# CY8C5888AXI_LP096 register map
File version: 0.1
CY8C58LP
Registers are 8-bit, read-write, no defined reset value unless marked. A register's access mark holds for its fields unless they carry their own. Offsets are from the block's base; lines under a group give offsets from that group; [hi:lo] are bit positions; {n}, {i} and the like mark numbered series; 'fields as' and 'values as' point back to an identical list; <NAME> marks a mode.

## Memory map
0x00000000 EZI2C_Slave
0x00000000 UART_1 — UART
0x00000000 USBUART — USBFS
0x00000000 Left_HB25_PWM
0x00000000 Left_QuadDec
0x00000000 Left_QuadDec_Cnt16
0x00000000 Right_QuadDec
0x00000000 Right_QuadDec_Cnt16
0x00000000 Right_HB25_PWM
0x40006472 Slave_Select

## UART_1 — UART
Base 0x00000000
0x40006428 RX_UART_1_RX_ADDRESS1 — RX Address1 Register
0x40006438 RX_UART_1_RX_ADDRESS2 — RX Address2 Register
0x40006448 RX_UART_1_RX_DATA — RX Data Register
0x4000644E TX_UART_1_TX_DATA — TX Data Register
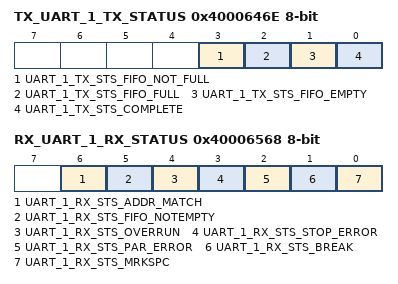
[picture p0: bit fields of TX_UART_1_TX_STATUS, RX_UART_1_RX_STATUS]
0x4000646E TX_UART_1_TX_STATUS — TX status register
  [3] UART_1_TX_STS_FIFO_NOT_FULL ro, [2] UART_1_TX_STS_FIFO_FULL ro, [1] UART_1_TX_STS_FIFO_EMPTY ro, [0] UART_1_TX_STS_COMPLETE ro
0x40006568 RX_UART_1_RX_STATUS — RX status register
  [6] UART_1_RX_STS_ADDR_MATCH ro, [5] UART_1_RX_STS_FIFO_NOTEMPTY ro, [4] UART_1_RX_STS_OVERRUN ro, [3] UART_1_RX_STS_STOP_ERROR ro, [2] UART_1_RX_STS_PAR_ERROR ro, [1] UART_1_RX_STS_BREAK ro, [0] UART_1_RX_STS_MRKSPC ro

## Slave_Select
Base 0x40006472
0x00 Slave_Select_CONTROL_REG

## Left_HB25_PWM
Base 0x00000000
0x40006424 Left_HB25_PWM_COMPARE_Reg 16-bit — UDB.D0 - Assigned Compare Value
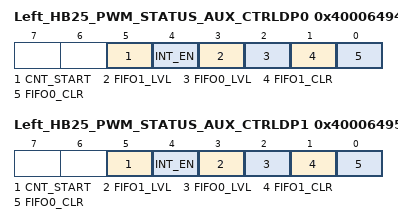
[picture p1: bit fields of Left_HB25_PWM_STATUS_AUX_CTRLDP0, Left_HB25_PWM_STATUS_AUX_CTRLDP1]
0x40006494 Left_HB25_PWM_STATUS_AUX_CTRLDP0 — UDB Auxilliary Control Register
  [5] CNT_START — FIFO0 clear
    0=E_CNT_START0 (Disable counter); 1=E_CNT_START1 (Enable counter)
  [4] INT_EN
    0=E_INT_EN0 (Interrupt disabled); 1=E_INT_EN1 (Interrupt enabled)
  [3] FIFO1_LVL — FIFO level
    0=E_FIFO_LVL_0 (FIFO LVL: input mode: FIFO not full; output mode: FIFO not empty); 1=E_FIFO_LVL_1 (FIFO LVL: input mode: FIFO at least 1/2 empty; output mode: FIFO at least 1/2 full)
  [2] FIFO0_LVL — FIFO level
    values as FIFO1_LVL
  [1] FIFO1_CLR — FIFO1 clear
    0=E_FIFO_CLR_0 (Normal FIFO operation); 1=E_FIFO_CLR_1 (Clear FIFO state)
  [0] FIFO0_CLR — FIFO0 clear
    values as FIFO1_CLR
0x40006495 Left_HB25_PWM_STATUS_AUX_CTRLDP1 — UDB Auxilliary Control Register
  fields as Left_HB25_PWM_STATUS_AUX_CTRLDP0

## Left_QuadDec
Base 0x00000000
0x4000640A Left_QuadDec_Cnt16_COUNTER 16-bit — Counter value
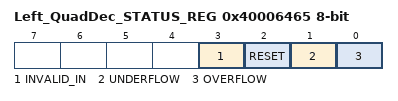
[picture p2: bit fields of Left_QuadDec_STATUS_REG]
0x40006465 Left_QuadDec_STATUS_REG — Quadrature Decoder Status Register
  [3] INVALID_IN ro — Invalid state transition on the A and B inputs
  [2] RESET ro — Counter Reset due index
  [1] UNDERFLOW ro — Counter underflow
  [0] OVERFLOW ro — Counter overflow

## Left_QuadDec_Cnt16
Base 0x00000000
0x4000640A Left_QuadDec_Cnt16_COUNTER 16-bit — UDB.A0 - Current Counter Value
0x4000642A Left_QuadDec_Cnt16_PERIOD 16-bit — UDB.D0 - Assigned Period
0x4000643A Left_QuadDec_Cnt16_COMPARE 16-bit — UDB.D1 - Assigned Compare Value
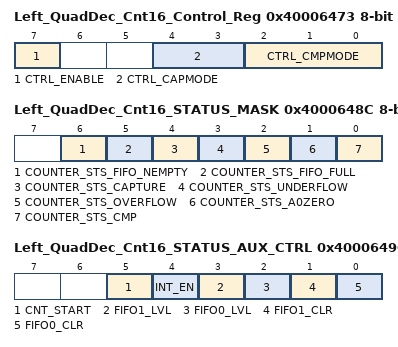
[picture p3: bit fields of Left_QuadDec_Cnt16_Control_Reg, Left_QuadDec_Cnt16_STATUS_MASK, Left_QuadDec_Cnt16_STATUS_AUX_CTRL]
0x40006473 Left_QuadDec_Cnt16_Control_Reg — UDB Control Register - Assigned Control Register Value
  [7] CTRL_ENABLE — Enable Counter
  [4:3] CTRL_CAPMODE — Capture mode
  [2:0] CTRL_CMPMODE — Compare mode
0x4000648C Left_QuadDec_Cnt16_STATUS_MASK — UDB Status bits Interrupt Mask Enable Register
  [6] COUNTER_STS_FIFO_NEMPTY — FIFO Not Empty Status
  [5] COUNTER_STS_FIFO_FULL — FIFO Full Status
  [4] COUNTER_STS_CAPTURE — Capture Status
  [3] COUNTER_STS_UNDERFLOW — Underflow status
  [2] COUNTER_STS_OVERFLOW — Overflow status
  [1] COUNTER_STS_A0ZERO — A0 Zero ouput status
  [0] COUNTER_STS_CMP — Compare output status
0x4000649C Left_QuadDec_Cnt16_STATUS_AUX_CTRL — UDB Auxilliary Control Register
  [5] CNT_START — FIFO0 clear
    0=E_CNT_START0 (Disable counter); 1=E_CNT_START1 (Enable counter)
  [4] INT_EN
    0=E_INT_EN0 (Interrupt disabled); 1=E_INT_EN1 (Interrupt enabled)
  [3] FIFO1_LVL — FIFO level
    0=E_FIFO_LVL_0 (FIFO LVL: input mode: FIFO not full; output mode: FIFO not empty); 1=E_FIFO_LVL_1 (FIFO LVL: input mode: FIFO at least 1/2 empty; output mode: FIFO at least 1/2 full)
  [2] FIFO0_LVL — FIFO level
    values as FIFO1_LVL
  [1] FIFO1_CLR — FIFO1 clear
    0=E_FIFO_CLR_0 (Normal FIFO operation); 1=E_FIFO_CLR_1 (Clear FIFO state)
  [0] FIFO0_CLR — FIFO0 clear
    values as FIFO1_CLR
